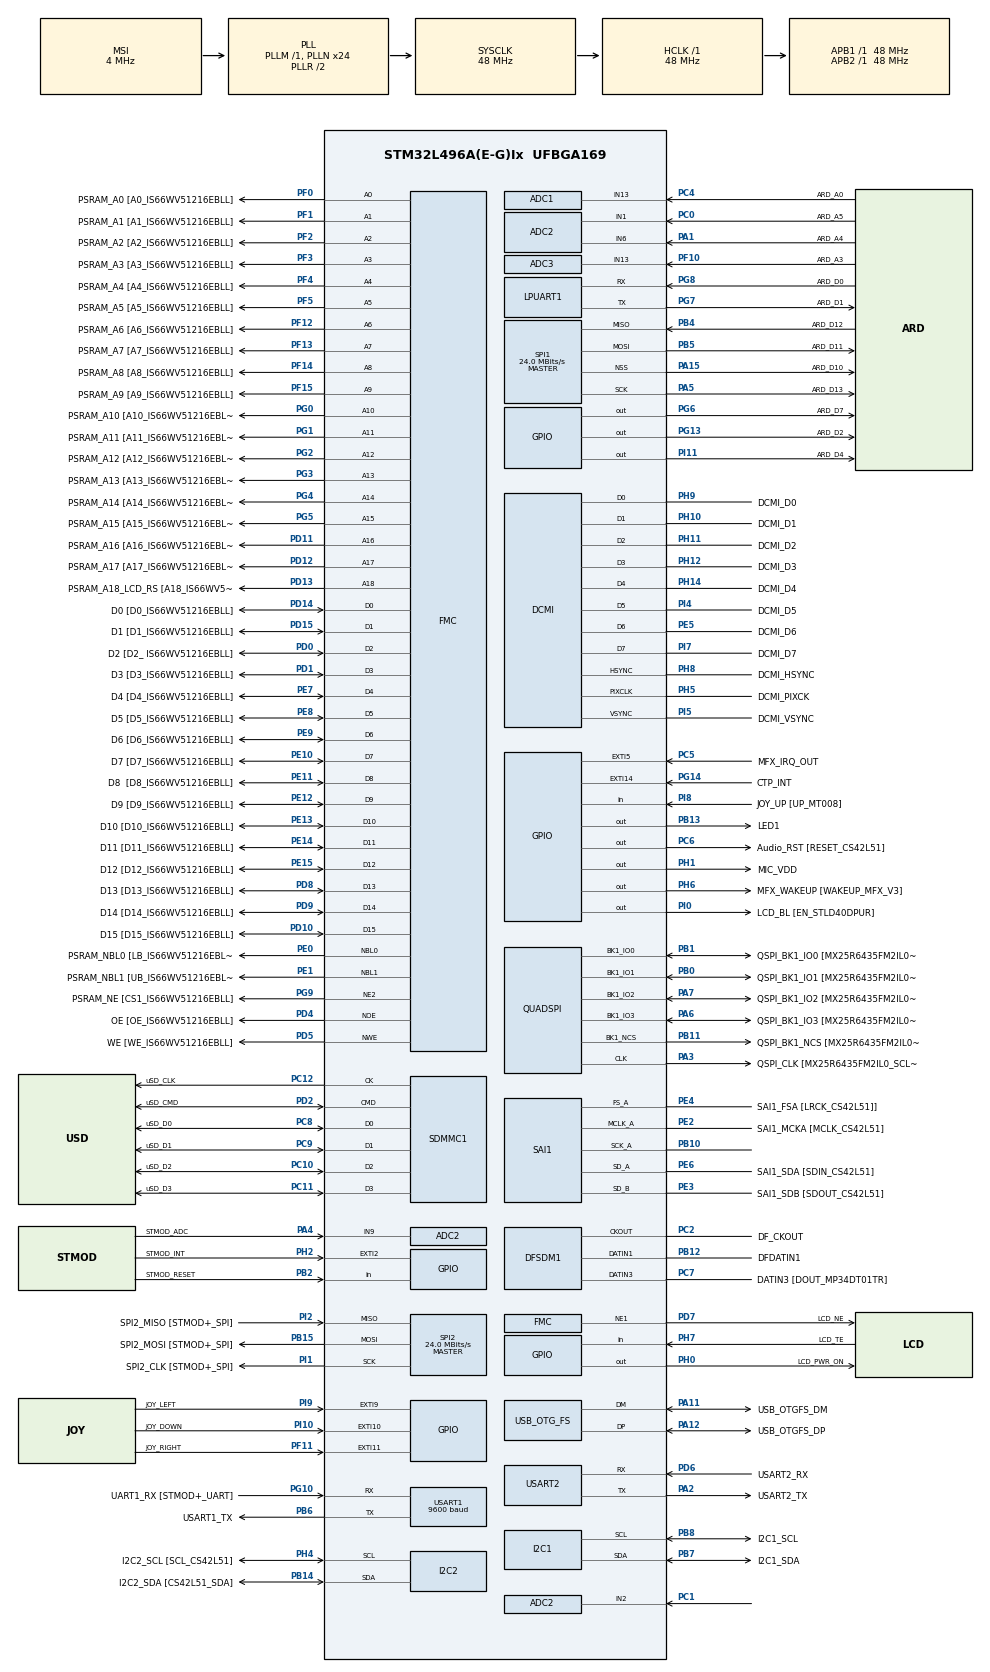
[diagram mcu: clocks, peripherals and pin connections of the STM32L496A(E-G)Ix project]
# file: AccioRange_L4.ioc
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ADC1.Channel-0\#ChannelRegularConversion=ADC_CHANNEL_13
ADC1.NbrOfConversionFlag=1
ADC1.OffsetNumber-0\#ChannelRegularConversion=ADC_OFFSET_NONE
ADC1.Rank-0\#ChannelRegularConversion=1
ADC1.Resolution=ADC_RESOLUTION_10B
ADC1.SamplingTime-0\#ChannelRegularConversion=ADC_SAMPLETIME_2CYCLES_5
ADC1.master=1
ADC2.Channel-0\#ChannelRegularConversion=ADC_CHANNEL_9
ADC2.NbrOfConversionFlag=1
ADC2.OffsetNumber-0\#ChannelRegularConversion=ADC_OFFSET_NONE
ADC2.Rank-0\#ChannelRegularConversion=1
ADC2.SamplingTime-0\#ChannelRegularConversion=ADC_SAMPLETIME_2CYCLES_5
ADC3.Channel-0\#ChannelRegularConversion=ADC_CHANNEL_13
ADC3.NbrOfConversionFlag=1
ADC3.OffsetNumber-0\#ChannelRegularConversion=ADC_OFFSET_NONE
ADC3.Rank-0\#ChannelRegularConversion=1
ADC3.SamplingTime-0\#ChannelRegularConversion=ADC_SAMPLETIME_2CYCLES_5
DCMI.JPEGMode=DCMI_JPEG_DISABLE
I2C1.Timing=0x20303E5D
I2C2.Timing=0x20303E5D
LPUART1.WordLength=UART_WORDLENGTH_8B
Mcu.Family=STM32L4
Mcu.Name=STM32L496A(E-G)Ix
Mcu.Package=UFBGA169
NVIC.EXTI15_10_IRQn=true\:0\:0\:false\:false\:true\:true\:true\:true
NVIC.EXTI9_5_IRQn=true\:0\:0\:false\:false\:true\:true\:true\:true
NVIC.OTG_FS_IRQn=true\:0\:0\:false\:false\:true\:true\:true\:true
NVIC.PriorityGroup=NVIC_PRIORITYGROUP_4
NVIC.TIM6_DAC_IRQn=true\:0\:0\:false\:false\:true\:true\:true\:true
PA0.GPIO_Label=STMOD_PWM
PA0.Mode=SYS_WakeUp0
PA0.Signal=SYS_WKUP1
PA1.GPIO_Label=ARD_A4
PA1.Signal=ADCx_IN6
PA10.GPIO_Label=USB_OTGFS_ID
PA10.Signal=USB_OTG_FS_ID
PA11.GPIO_Label=USB_OTGFS_DM
PA11.Mode=Device_Only
PA11.Signal=USB_OTG_FS_DM
PA12.GPIO_Label=USB_OTGFS_DP
PA12.Mode=Device_Only
PA12.Signal=USB_OTG_FS_DP
PA13\ (JTMS/SWDIO).GPIO_Label=SWDIO
PA13\ (JTMS/SWDIO).Mode=Serial_Wire
PA13\ (JTMS/SWDIO).Signal=SYS_JTMS-SWDIO
PA14\ (JTCK/SWCLK).GPIO_Label=SWCLK
PA14\ (JTCK/SWCLK).Mode=Serial_Wire
PA14\ (JTCK/SWCLK).Signal=SYS_JTCK-SWCLK
PA15\ (JTDI).GPIO_Label=ARD_D10
PA15\ (JTDI).Mode=NSS_Signal_Hard_Output
PA15\ (JTDI).Signal=SPI1_NSS
PA2.GPIO_Label=USART2_TX
PA2.Mode=Asynchronous
PA2.Signal=USART2_TX
PA3.GPIO_Label=QSPI_CLK [MX25R6435FM2IL0_SCLK]
PA3.Mode=Single Bank 1
PA3.Signal=QUADSPI_CLK
PA4.GPIO_Label=STMOD_ADC
PA4.Signal=ADCx_IN9
PA5.GPIO_Label=ARD_D13
PA5.Mode=Full_Duplex_Master
PA5.Signal=SPI1_SCK
PA6.GPIO_Label=QSPI_BK1_IO3 [MX25R6435FM2IL0_SIO3]
PA6.Mode=Single Bank 1
PA6.Signal=QUADSPI_BK1_IO3
PA7.GPIO_Label=QSPI_BK1_IO2 [MX25R6435FM2IL0_SIO2]
PA7.Mode=Single Bank 1
PA7.Signal=QUADSPI_BK1_IO2
PA8.GPIO_Label=DCMI_CLK
PA8.Signal=LPTIM2_OUT
PA9.GPIO_Label=USB_OTGFS_VBUS
PA9.Signal=USB_OTG_FS_VBUS
PB0.GPIO_Label=QSPI_BK1_IO1 [MX25R6435FM2IL0_SIO1]
PB0.Mode=Single Bank 1
PB0.Signal=QUADSPI_BK1_IO1
PB1.GPIO_Label=QSPI_BK1_IO0 [MX25R6435FM2IL0_SIO0]
PB1.Mode=Single Bank 1
PB1.Signal=QUADSPI_BK1_IO0
PB10.Mode=SAI_A_MasterWithClock
PB10.Signal=SAI1_SCK_A
PB11.GPIO_Label=QSPI_BK1_NCS [MX25R6435FM2IL0_CS]
PB11.Mode=Single Bank 1
PB11.Signal=QUADSPI_BK1_NCS
PB12.GPIO_Label=DFDATIN1
PB12.Signal=S_DATAIN1DFSDM1
PB13.GPIO_Label=LED1
PB13.GPIO_ModeDefaultOutputPP=GPIO_MODE_OUTPUT_OD
PB13.GPIO_PuPd=GPIO_NOPULL
PB13.Signal=GPIO_Output
PB14.GPIO_Label=I2C2_SDA [CS42L51_SDA]
PB14.GPIO_Pu=GPIO_PULLUP
PB14.Mode=I2C
PB14.Signal=I2C2_SDA
PB15.GPIO_Label=SPI2_MOSI [STMOD+_SPI]
PB15.Mode=Full_Duplex_Master
PB15.Signal=SPI2_MOSI
PB2.GPIO_Label=STMOD_RESET
PB2.Signal=GPIO_Input
PB3\ (JTDO/TRACESWO).GPIO_Label=SWO
PB3\ (JTDO/TRACESWO).Signal=SYS_JTDO-SWO
PB4\ (NJTRST).GPIO_Label=ARD_D12
PB4\ (NJTRST).Mode=Full_Duplex_Master
PB4\ (NJTRST).Signal=SPI1_MISO
PB5.GPIO_Label=ARD_D11
PB5.Mode=Full_Duplex_Master
PB5.Signal=SPI1_MOSI
PB6.GPIO_Label=USART1_TX
PB6.Mode=Asynchronous
PB6.Signal=USART1_TX
PB7.GPIO_Label=I2C1_SDA
PB7.GPIO_Pu=GPIO_PULLUP
PB7.Mode=I2C
PB7.Signal=I2C1_SDA
PB8.GPIO_Label=I2C1_SCL
PB8.GPIO_Pu=GPIO_PULLUP
PB8.Mode=I2C
PB8.Signal=I2C1_SCL
PB9.GPIO_Label=ARD_D5
PB9.Signal=S_TIM4_CH4
PC0.GPIO_Label=ARD_A5
PC0.Signal=ADCx_IN1
PC1.Signal=ADCx_IN2
PC10.GPIO_Label=uSD_D2
PC10.Mode=SD_4_bits_Wide_bus
PC10.Signal=SDMMC1_D2
PC11.GPIO_Label=uSD_D3
PC11.Mode=SD_4_bits_Wide_bus
PC11.Signal=SDMMC1_D3
PC12.GPIO_Label=uSD_CLK
PC12.Mode=SD_4_bits_Wide_bus
PC12.Signal=SDMMC1_CK
PC13.GPIO_Label=JOY_SEL [Selection_MT008]
PC13.Mode=SYS_WakeUp1
PC13.Signal=SYS_WKUP2
PC14-OSC32_IN\ (PC14).Mode=LSE-External-Oscillator
PC14-OSC32_IN\ (PC14).Signal=RCC_OSC32_IN
PC15-OSC32_OUT\ (PC15).Mode=LSE-External-Oscillator
PC15-OSC32_OUT\ (PC15).Signal=RCC_OSC32_OUT
PC2.GPIO_Label=DF_CKOUT
PC2.Signal=S_CKOUTDFSDM1
PC3.GPIO_Label=ARD_A2
PC3.Signal=ADCx_IN4
PC4.GPIO_Label=ARD_A0
PC4.Signal=ADCx_IN13
PC5.GPIO_Label=MFX_IRQ_OUT
PC5.Signal=GPXTI5
PC6.GPIO_Label=Audio_RST [RESET_CS42L51]
PC6.Signal=GPIO_Output
PC7.GPIO_Label=DATIN3 [DOUT_MP34DT01TR]
PC7.Signal=S_DATAIN3DFSDM1
PC8.GPIO_Label=uSD_D0
PC8.Mode=SD_4_bits_Wide_bus
PC8.Signal=SDMMC1_D0
PC9.GPIO_Label=uSD_D1
PC9.Mode=SD_4_bits_Wide_bus
PC9.Signal=SDMMC1_D1
PD0.GPIO_Label=D2 [D2_ IS66WV51216EBLL]
PD0.Signal=FMC_D2_DA2
PD1.GPIO_Label=D3 [D3_IS66WV51216EBLL]
PD1.Signal=FMC_D3_DA3
PD10.GPIO_Label=D15 [D15_IS66WV51216EBLL]
PD10.Signal=FMC_D15_DA15
PD11.GPIO_Label=PSRAM_A16 [A16_IS66WV51216EBLL]
PD11.Signal=FMC_A16_CLE
PD12.GPIO_Label=PSRAM_A17 [A17_IS66WV51216EBLL]
PD12.Signal=FMC_A17_ALE
PD13.GPIO_Label=PSRAM_A18_LCD_RS [A18_IS66WV51216EBLL]
PD13.Signal=FMC_A18
PD14.GPIO_Label=D0 [D0_IS66WV51216EBLL]
PD14.Signal=FMC_D0_DA0
PD15.GPIO_Label=D1 [D1_IS66WV51216EBLL]
PD15.Signal=FMC_D1_DA1
PD2.GPIO_Label=uSD_CMD
PD2.Mode=SD_4_bits_Wide_bus
PD2.Signal=SDMMC1_CMD
PD4.GPIO_Label=OE [OE_IS66WV51216EBLL]
PD4.Signal=FMC_NOE
PD5.GPIO_Label=WE [WE_IS66WV51216EBLL]
PD5.Signal=FMC_NWE
PD6.GPIO_Label=USART2_RX
PD6.Mode=Asynchronous
PD6.Signal=USART2_RX
PD7.GPIO_Label=LCD_NE
PD7.Mode=NorPsramChipSelect1_2
PD7.Signal=FMC_NE1
PD8.GPIO_Label=D13 [D13_IS66WV51216EBLL]
PD8.Signal=FMC_D13_DA13
PD9.GPIO_Label=D14 [D14_IS66WV51216EBLL]
PD9.Signal=FMC_D14_DA14
PE0.GPIO_Label=PSRAM_NBL0 [LB_IS66WV51216EBLL]
PE0.Signal=FMC_NBL0
PE1.GPIO_Label=PSRAM_NBL1 [UB_IS66WV51216EBLL]
PE1.Signal=FMC_NBL1
PE10.GPIO_Label=D7 [D7_IS66WV51216EBLL]
PE10.Signal=FMC_D7_DA7
PE11.GPIO_Label=D8  [D8_IS66WV51216EBLL]
PE11.Signal=FMC_D8_DA8
PE12.GPIO_Label=D9 [D9_IS66WV51216EBLL]
PE12.Signal=FMC_D9_DA9
PE13.GPIO_Label=D10 [D10_IS66WV51216EBLL]
PE13.Signal=FMC_D10_DA10
PE14.GPIO_Label=D11 [D11_IS66WV51216EBLL]
PE14.Signal=FMC_D11_DA11
PE15.GPIO_Label=D12 [D12_IS66WV51216EBLL]
PE15.Signal=FMC_D12_DA12
PE2.GPIO_Label=SAI1_MCKA [MCLK_CS42L51]
PE2.Mode=SAI_A_MasterWithClock
PE2.Signal=SAI1_MCLK_A
PE3.GPIO_Label=SAI1_SDB [SDOUT_CS42L51]
PE3.Mode=SAI_B_SyncSlave
PE3.Signal=SAI1_SD_B
PE4.GPIO_Label=SAI1_FSA [LRCK_CS42L51]]
PE4.Mode=SAI_A_MasterWithClock
PE4.Signal=SAI1_FS_A
PE5.GPIO_Label=DCMI_D6
PE5.Mode=Slave_8_bits_External_Synchro
PE5.Signal=DCMI_D6
PE6.GPIO_Label=SAI1_SDA [SDIN_CS42L51]
PE6.Mode=SAI_A_MasterWithClock
PE6.Signal=SAI1_SD_A
PE7.GPIO_Label=D4 [D4_IS66WV51216EBLL]
PE7.Signal=FMC_D4_DA4
PE8.GPIO_Label=D5 [D5_IS66WV51216EBLL]
PE8.Signal=FMC_D5_DA5
PE9.GPIO_Label=D6 [D6_IS66WV51216EBLL]
PE9.Signal=FMC_D6_DA6
PF0.GPIO_Label=PSRAM_A0 [A0_IS66WV51216EBLL]
PF0.Signal=FMC_A0
PF1.GPIO_Label=PSRAM_A1 [A1_IS66WV51216EBLL]
PF1.Signal=FMC_A1
PF10.GPIO_Label=ARD_A3
PF10.Mode=IN13-Single-Ended
PF10.Signal=ADC3_IN13
PF11.GPIO_Label=JOY_RIGHT
PF11.GPIO_PuPd=GPIO_PULLDOWN
PF11.Signal=GPXTI11
PF12.GPIO_Label=PSRAM_A6 [A6_IS66WV51216EBLL]
PF12.Signal=FMC_A6
PF13.GPIO_Label=PSRAM_A7 [A7_IS66WV51216EBLL]
PF13.Signal=FMC_A7
PF14.GPIO_Label=PSRAM_A8 [A8_IS66WV51216EBLL]
PF14.Signal=FMC_A8
PF15.GPIO_Label=PSRAM_A9 [A9_IS66WV51216EBLL]
PF15.Signal=FMC_A9
PF2.GPIO_Label=PSRAM_A2 [A2_IS66WV51216EBLL]
PF2.Signal=FMC_A2
PF3.GPIO_Label=PSRAM_A3 [A3_IS66WV51216EBLL]
PF3.Signal=FMC_A3
PF4.GPIO_Label=PSRAM_A4 [A4_IS66WV51216EBLL]
PF4.Signal=FMC_A4
PF5.GPIO_Label=PSRAM_A5 [A5_IS66WV51216EBLL]
PF5.Signal=FMC_A5
PG0.GPIO_Label=PSRAM_A10 [A10_IS66WV51216EBLL]
PG0.Signal=FMC_A10
PG1.GPIO_Label=PSRAM_A11 [A11_IS66WV51216EBLL]
PG1.Signal=FMC_A11
PG10.GPIO_Label=UART1_RX [STMOD+_UART]
PG10.Mode=Asynchronous
PG10.Signal=USART1_RX
PG11.GPIO_Label=UART1_CTS [STMOD+_UART]
PG11.Signal=USART1_CTS
PG12.GPIO_Label=UART1_RTS [STMOD+_UART]
PG12.Signal=USART1_RTS
PG13.GPIO_Label=ARD_D2
PG13.Signal=GPIO_Output
PG14.GPIO_Label=CTP_INT
PG14.Signal=GPXTI14
PG2.GPIO_Label=PSRAM_A12 [A12_IS66WV51216EBLL]
PG2.Signal=FMC_A12
PG3.GPIO_Label=PSRAM_A13 [A13_IS66WV51216EBLL]
PG3.Signal=FMC_A13
PG4.GPIO_Label=PSRAM_A14 [A14_IS66WV51216EBLL]
PG4.Signal=FMC_A14
PG5.GPIO_Label=PSRAM_A15 [A15_IS66WV51216EBLL]
PG5.Signal=FMC_A15
PG6.GPIO_Label=ARD_D7
PG6.Signal=GPIO_Output
PG7.GPIO_Label=ARD_D1
PG7.Mode=Asynchronous
PG7.Signal=LPUART1_TX
PG8.GPIO_Label=ARD_D0
PG8.Mode=Asynchronous
PG8.Signal=LPUART1_RX
PG9.GPIO_Label=PSRAM_NE [CS1_IS66WV51216EBLL]
PG9.Mode=NorPsramChipSelect2_1
PG9.Signal=FMC_NE2
PH0-OSC_IN\ (PH0).GPIO_Label=LCD_PWR_ON
PH0-OSC_IN\ (PH0).Signal=GPIO_Output
PH1-OSC_OUT\ (PH1).GPIO_Label=MIC_VDD
PH1-OSC_OUT\ (PH1).Signal=GPIO_Output
PH10.GPIO_Label=DCMI_D1
PH10.Mode=Slave_8_bits_External_Synchro
PH10.Signal=DCMI_D1
PH11.GPIO_Label=DCMI_D2
PH11.Mode=Slave_8_bits_External_Synchro
PH11.Signal=DCMI_D2
PH12.GPIO_Label=DCMI_D3
PH12.Mode=Slave_8_bits_External_Synchro
PH12.Signal=DCMI_D3
PH13.GPIO_Label=ARD_D9
PH13.Signal=TIM8_CH1N
PH14.GPIO_Label=DCMI_D4
PH14.Mode=Slave_8_bits_External_Synchro
PH14.Signal=DCMI_D4
PH15.GPIO_Label=ARD_D3
PH15.Signal=TIM8_CH3N
PH2.GPIO_Label=STMOD_INT
PH2.Signal=GPXTI2
PH4.GPIO_Label=I2C2_SCL [SCL_CS42L51]
PH4.GPIO_Pu=GPIO_PULLUP
PH4.Mode=I2C
PH4.Signal=I2C2_SCL
PH5.GPIO_Label=DCMI_PIXCK
PH5.Mode=Slave_8_bits_External_Synchro
PH5.Signal=DCMI_PIXCLK
PH6.GPIO_Label=MFX_WAKEUP [WAKEUP_MFX_V3]
PH6.Signal=GPIO_Output
PH7.GPIO_Label=LCD_TE
PH7.Signal=GPIO_Input
PH8.GPIO_Label=DCMI_HSYNC
PH8.Mode=Slave_8_bits_External_Synchro
PH8.Signal=DCMI_HSYNC
PH9.GPIO_Label=DCMI_D0
PH9.Mode=Slave_8_bits_External_Synchro
PH9.Signal=DCMI_D0
PI0.GPIO_Label=LCD_BL [EN_STLD40DPUR]
PI0.Signal=GPIO_Output
PI1.GPIO_Label=SPI2_CLK [STMOD+_SPI]
PI1.Mode=Full_Duplex_Master
PI1.Signal=SPI2_SCK
PI10.GPIO_Label=JOY_DOWN
PI10.GPIO_PuPd=GPIO_PULLDOWN
PI10.Signal=GPXTI10
PI11.GPIO_Label=ARD_D4
PI11.Signal=GPIO_Output
PI2.GPIO_Label=SPI2_MISO [STMOD+_SPI]
PI2.Mode=Full_Duplex_Master
PI2.Signal=SPI2_MISO
PI4.GPIO_Label=DCMI_D5
PI4.Mode=Slave_8_bits_External_Synchro
PI4.Signal=DCMI_D5
PI5.GPIO_Label=DCMI_VSYNC
PI5.Mode=Slave_8_bits_External_Synchro
PI5.Signal=DCMI_VSYNC
PI6.GPIO_Label=ARD_D6
PI6.Signal=S_TIM8_CH2
PI7.GPIO_Label=DCMI_D7
PI7.Mode=Slave_8_bits_External_Synchro
PI7.Signal=DCMI_D7
PI8.GPIO_Label=JOY_UP [UP_MT008]
PI8.GPIO_PuPd=GPIO_PULLDOWN
PI8.Signal=GPIO_Input
PI9.GPIO_Label=JOY_LEFT
PI9.GPIO_ModeDefaultEXTI=GPIO_MODE_EVT_RISING
PI9.GPIO_PuPd=GPIO_PULLDOWN
PI9.Signal=GPXTI9
ProjectManager.HeapSize=0x200
ProjectManager.StackSize=0x400
ProjectManager.TargetToolchain=STM32CubeIDE
QUADSPI.ClockPrescaler=2
QUADSPI.FifoThreshold=4
QUADSPI.FlashSize=23
QUADSPI.SampleShifting=QSPI_SAMPLE_SHIFTING_HALFCYCLE
RCC.ADCFreq_Value=48000000
RCC.AHBFreq_Value=48000000
RCC.APB1Freq_Value=48000000
RCC.APB1TimFreq_Value=48000000
RCC.APB2Freq_Value=48000000
RCC.APB2TimFreq_Value=48000000
RCC.CortexFreq_Value=48000000
RCC.HCLKFreq_Value=48000000
RCC.HSE_VALUE=8000000
RCC.HSI48_VALUE=48000000
RCC.HSI_VALUE=16000000
RCC.MSI_VALUE=4000000
RCC.PLLN=24
RCC.PLLSAI1N=24
RCC.SYSCLKFreq_VALUE=48000000
RCC.SYSCLKSource=RCC_SYSCLKSOURCE_PLLCLK
RCC.USBFreq_Value=48000000
RCC.VCOOutputFreq_Value=96000000
SAI1.ErrorAudioFreq-SAI_A_MasterWithClock=-2.34 %
SAI1.Instance-SAI_A_MasterWithClock=SAI$Index_Block_A
SAI1.Instance-SAI_B_SyncSlave=SAI$Index_Block_B
SAI1.MClockEnable-SAI_A_MasterWithClock=SAI_MASTERCLOCK_ENABLE
SAI1.RealAudioFreq-SAI_A_MasterWithClock=187.5 KHz
SAI1.VirtualMode-SAI_A_MasterWithClock=VM_MASTER
SAI1.VirtualMode-SAI_B_SyncSlave=VM_SLAVE
SH.ADCx_IN1.0=ADC2_IN1,IN1-Single-Ended
SH.ADCx_IN13.0=ADC1_IN13,IN13-Single-Ended
SH.ADCx_IN2.0=ADC2_IN2,IN2-Single-Ended
SH.ADCx_IN4.0=ADC1_IN4
SH.ADCx_IN6.0=ADC2_IN6,IN6-Single-Ended
SH.ADCx_IN9.0=ADC2_IN9,IN9-Single-Ended
SH.FMC_A0.0=FMC_A0,18b-a1
SH.FMC_A1.0=FMC_A1,18b-a1
SH.FMC_A10.0=FMC_A10,18b-a1
SH.FMC_A11.0=FMC_A11,18b-a1
SH.FMC_A12.0=FMC_A12,18b-a1
SH.FMC_A13.0=FMC_A13,18b-a1
SH.FMC_A14.0=FMC_A14,18b-a1
SH.FMC_A15.0=FMC_A15,18b-a1
SH.FMC_A16_CLE.0=FMC_A16,18b-a1
SH.FMC_A17_ALE.0=FMC_A17,18b-a1
SH.FMC_A18.0=FMC_A18,A18_2
SH.FMC_A2.0=FMC_A2,18b-a1
SH.FMC_A3.0=FMC_A3,18b-a1
SH.FMC_A4.0=FMC_A4,18b-a1
SH.FMC_A5.0=FMC_A5,18b-a1
SH.FMC_A6.0=FMC_A6,18b-a1
SH.FMC_A7.0=FMC_A7,18b-a1
SH.FMC_A8.0=FMC_A8,18b-a1
SH.FMC_A9.0=FMC_A9,18b-a1
SH.FMC_D0_DA0.0=FMC_D0,16b-d1
SH.FMC_D0_DA0.1=FMC_D0,16b-d2
SH.FMC_D10_DA10.0=FMC_D10,16b-d1
SH.FMC_D10_DA10.1=FMC_D10,16b-d2
SH.FMC_D11_DA11.0=FMC_D11,16b-d1
SH.FMC_D11_DA11.1=FMC_D11,16b-d2
SH.FMC_D12_DA12.0=FMC_D12,16b-d1
SH.FMC_D12_DA12.1=FMC_D12,16b-d2
SH.FMC_D13_DA13.0=FMC_D13,16b-d1
SH.FMC_D13_DA13.1=FMC_D13,16b-d2
SH.FMC_D14_DA14.0=FMC_D14,16b-d1
SH.FMC_D14_DA14.1=FMC_D14,16b-d2
SH.FMC_D15_DA15.0=FMC_D15,16b-d1
SH.FMC_D15_DA15.1=FMC_D15,16b-d2
SH.FMC_D1_DA1.0=FMC_D1,16b-d1
SH.FMC_D1_DA1.1=FMC_D1,16b-d2
SH.FMC_D2_DA2.0=FMC_D2,16b-d1
SH.FMC_D2_DA2.1=FMC_D2,16b-d2
SH.FMC_D3_DA3.0=FMC_D3,16b-d1
SH.FMC_D3_DA3.1=FMC_D3,16b-d2
SH.FMC_D4_DA4.0=FMC_D4,16b-d1
SH.FMC_D4_DA4.1=FMC_D4,16b-d2
SH.FMC_D5_DA5.0=FMC_D5,16b-d1
SH.FMC_D5_DA5.1=FMC_D5,16b-d2
SH.FMC_D6_DA6.0=FMC_D6,16b-d1
SH.FMC_D6_DA6.1=FMC_D6,16b-d2
SH.FMC_D7_DA7.0=FMC_D7,16b-d1
SH.FMC_D7_DA7.1=FMC_D7,16b-d2
SH.FMC_D8_DA8.0=FMC_D8,16b-d1
SH.FMC_D8_DA8.1=FMC_D8,16b-d2
SH.FMC_D9_DA9.0=FMC_D9,16b-d1
SH.FMC_D9_DA9.1=FMC_D9,16b-d2
SH.FMC_NBL0.0=FMC_NBL0,2ByteEnable1
SH.FMC_NBL1.0=FMC_NBL1,2ByteEnable1
SH.FMC_NOE.0=FMC_NOE,Sram1
SH.FMC_NOE.1=FMC_NOE,Lcd2
SH.FMC_NWE.0=FMC_NWE,Sram1
SH.FMC_NWE.1=FMC_NWE,Lcd2
SH.S_CKOUTDFSDM1.0=DFSDM1_CKOUT,PDM_SPI_Input_from_ch23_and_Internal_Clock
SH.S_CKOUTDFSDM1.1=DFSDM1_CKOUT,PDM_SPI_input_from_ch1_and_internal_clock
SH.S_DATAIN1DFSDM1.0=DFSDM1_DATIN1,PDM_SPI_input_from_ch1_and_internal_clock
SH.S_DATAIN3DFSDM1.0=DFSDM1_DATIN3,PDM_SPI_Input_from_ch23_and_Internal_Clock
SH.S_TIM4_CH4.0=TIM4_CH4
SH.S_TIM8_CH2.0=TIM8_CH2
SPI1.CalculateBaudRate=24.0 MBits/s
SPI1.Direction=SPI_DIRECTION_2LINES
SPI1.Mode=SPI_MODE_MASTER
SPI1.VirtualNSS=VM_NSSHARD
SPI1.VirtualType=VM_MASTER
SPI2.CalculateBaudRate=24.0 MBits/s
SPI2.Direction=SPI_DIRECTION_2LINES
SPI2.Mode=SPI_MODE_MASTER
SPI2.VirtualType=VM_MASTER
TIM6.Period=19200-1
TIM6.Prescaler=100-1
USART1.BaudRate=9600
USART1.VirtualMode-Asynchronous=VM_ASYNC
USART2.VirtualMode-Asynchronous=VM_ASYNC
USB_DEVICE.CLASS_NAME_FS=CDC
USB_DEVICE.VirtualMode=Cdc
USB_DEVICE.VirtualModeFS=Cdc_FS
USB_OTG_FS.VirtualMode=Device_Only
VP_TIM6_VS_ClockSourceINT.Mode=Enable_Timer
VP_USB_DEVICE_VS_USB_DEVICE_CDC_FS.Mode=CDC_FS
board=STM32L496G-DISCO

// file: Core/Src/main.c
/* USER CODE BEGIN Header */
/**
  ******************************************************************************
  * @file           : main.c
  * @brief          : Main program body
  ******************************************************************************
  * @attention
  *
  * Copyright (c) 2022 STMicroelectronics.
  * All rights reserved.
  *
  * This software is licensed under terms that can be found in the LICENSE file
  * in the root directory of this software component.
  * If no LICENSE file comes with this software, it is provided AS-IS.
  *
  ******************************************************************************
  */
/* USER CODE END Header */
#include "main.h"
#include "adc.h"
#include "dcmi.h"
#include "dfsdm.h"
#include "i2c.h"
#include "usart.h"
#include "quadspi.h"
#include "sai.h"
#include "sdmmc.h"
#include "spi.h"
#include "tim.h"
#include "usb_device.h"
#include "gpio.h"
#include "fmc.h"

/* USER CODE BEGIN Includes */
// be sure to add these directories to the build paths in project properties
#include <stdbool.h>
#include "vl53l0x_api.h"
#include "stm32l496g_discovery.h"
#include "stm32l496g_discovery_lcd.h"
#include "stm32l496g_discovery_ts.h"
/* USER CODE END Includes */

/* USER CODE BEGIN PD */
#define TIMED_RANGING_PERIOD    40    // sensor sampling period in ms
#define LED_TOGGLE_DELAY        100   // heartbeat led
#define PWR_ANALYSIS 						1     // set to 1 to have longer delays when powering down peripherals
#define PWR_ANALYSIS_DELAY			1000  // duration of delay
#define RANGER_SAMPLE_RATE      20    // samples per second
#define PROFILING_TIM           0     // set to 1 to trigger test point whenever timer interrupt fires
#define PROFILING_SAMPLES       1     // set to 1 to trigger test point during processing of samples
/* USER CODE END PD */

/* USER CODE BEGIN PV */

// touch screen related
TS_StateTypeDef ts_result;
uint32_t last_ts;
char buf[20];

// states related
bool SAMPLE_SENSOR = false;
bool DIMMED_SCREEN = false;
bool SLEEP_MODE_ACTIVE = false;
bool ENTER_SLEEP_MODE = false;
bool BT_ENABLED = true;
bool SEND_ENABLED = true;

// led related
bool led_on = false;
static uint32_t TimingDelay;

// ui related // UI234
struct Bubble {
   uint16_t x;
   uint16_t y;
   uint16_t radius;
   uint16_t hit_diameter;
   bool selected;
   uint16_t colour_active;
   uint16_t colour_inactive;
   bool redraw;
   uint8_t type;
   uint32_t last_selected;
};
uint8_t num_bubbles = 4;
struct Bubble ui_bubbles[4];
bool bubble_label_redraw = true;

// tof related
VL53L0X_RangingMeasurementData_t RangingMeasurementData; // global ranging struct

VL53L0X_Dev_t VL53L0XDev = {
		.Id=0,
		.DevLetter='e',
		.I2cHandle=&hi2c1,
		.I2cDevAddr=0x29 // EK: documentation says address is 0x29, why did the code say 0x52?
};

uint8_t VhvSettings;
uint8_t PhaseCal;
uint32_t refSpadCount;
uint8_t isApertureSpads;

// sampling related
struct Ranger {
	uint16_t max;
	uint16_t min;

	uint16_t raw;
	float raw_mm;

	float raw_sum;
	uint16_t sum_count;
	uint16_t sum_skip;

	float mm_avg;

	uint16_t record_index;
	float records[300];
	bool process_records;
	float record_sum;

	float val;
};
uint8_t num_rangers = 2;
struct Ranger rangers[2];

uint16_t NUM_RECORDS = 5;
uint16_t MAX_RECORDS = 300; // =5mins*60seconds

float sonar_mm_avg = 0.0;
float tof_mm_avg = 0.0;

float result_distance = 0.0;
bool UPDATE_RESULT = false;
float alpha = 0.75; // weight of tof

/* USER CODE END PV */

void SystemClock_Config(void);
void PeriphCommonClock_Config(void);
/* USER CODE BEGIN PFP */

// sleep mode related
void reconfigureFromSleep(void);
void awakeFromSleep(void);
void enterSleep(void);

// ui related
void uiSetup(void);
void drawBubble(struct Bubble *bubble);
void deselectBubbles(uint8_t skip);

// tof related
void tofTestRegisterRead(void);

/* USER CODE END PFP */

/* USER CODE BEGIN 0 */

/**
 * Handle Error
 *
 * Set err on display and loop forever
 * @param err Error case code
 */
void HandleError(int err){
    char msg[16];
    sprintf(msg,"Er%d", err);
    while(1){};
}

void HAL_TIM_PeriodElapsedCallback(TIM_HandleTypeDef *htim) {

	if(htim == &htim6) {
		if(PROFILING_TIM) HAL_GPIO_TogglePin(ARD_D7_GPIO_Port, ARD_D7_Pin); // test point for profiling
		SAMPLE_SENSOR = true;
	}

}

/* USER CODE END 0 */

int main(void)
{

  /* MCU Configuration--------------------------------------------------------*/

  /* Reset of all peripherals, Initializes the Flash interface and the Systick. */
  HAL_Init();

  /* Configure the system clock */
  SystemClock_Config();

/* Configure the peripherals common clocks */
  PeriphCommonClock_Config();

  /* Initialize all configured peripherals */
  MX_GPIO_Init();
  MX_ADC1_Init();
  MX_ADC2_Init();
  MX_ADC3_Init();
  MX_DCMI_Init();
  MX_DFSDM1_Init();
  MX_FMC_Init();
  MX_I2C1_Init();
  MX_I2C2_Init();
  MX_LPUART1_UART_Init();
  MX_USART1_UART_Init();
  MX_USART2_UART_Init();
  MX_QUADSPI_Init();
  MX_SAI1_Init();
  MX_SDMMC1_SD_Init();
  MX_SPI1_Init();
  MX_SPI2_Init();
  MX_USB_DEVICE_Init();
  MX_TIM6_Init();
  /* USER CODE BEGIN 2 */
  // above: MX_SDMMC1_SD_Init(); has to be commented out to not be called

  // lcd init
	if (BSP_LCD_InitEx(LCD_ORIENTATION_LANDSCAPE) == LCD_ERROR) {
		Error_Handler();
	}

	// touchscreen init
	if(BSP_TS_InitEx(BSP_LCD_GetXSize(), BSP_LCD_GetYSize(), LCD_ORIENTATION_LANDSCAPE) != TS_OK) {
		Error_Handler();
	}

	// LED GPIO
	BSP_LED_Init(LED2_PIN); // LD1
	BSP_LED_On(LED2_PIN); // LD1 orange turns on
	HAL_GPIO_WritePin(LED2_GPIO_PORT, LED2_PIN, GPIO_PIN_RESET); // LD2 green turns on
	// LD3 is attached to ARD_D13, which is not an output, it's attached to SPI
	HAL_GPIO_WritePin(ARD_D4_GPIO_Port, ARD_D4_Pin, GPIO_PIN_RESET); // laser
	HAL_GPIO_WritePin(ARD_D7_GPIO_Port, ARD_D7_Pin, GPIO_PIN_RESET); // test point: timer frequency
	HAL_GPIO_WritePin(ARD_D2_GPIO_Port, ARD_D2_Pin, GPIO_PIN_SET); // turn on BT pwr transistor

	// tof related
	VL53L0X_Dev_t *pDev;
	pDev = &VL53L0XDev;
	tofTestRegisterRead();

	pDev->I2cDevAddr = 0x52;
	pDev->Present = 0;

	int status = VL53L0X_DataInit(pDev);
	if(status == 0) {
			pDev->Present = 1;
	} else {
			printf("VL53L0X_DataInit fail\n");
			return;
	}
	printf("VL53L0X %d Present and initiated to final 0x%x\n", pDev->Id, pDev->I2cDevAddr);
	pDev->Present = 1;

	// Initialize the device in continuous ranging mode
	VL53L0X_StaticInit(pDev);
	VL53L0X_PerformRefCalibration(pDev, &VhvSettings, &PhaseCal);
	VL53L0X_PerformRefSpadManagement(pDev, &refSpadCount, &isApertureSpads);
	VL53L0X_SetInterMeasurementPeriodMilliSeconds(pDev, TIMED_RANGING_PERIOD);
	VL53L0X_SetDeviceMode(pDev, VL53L0X_DEVICEMODE_CONTINUOUS_TIMED_RANGING);
	VL53L0X_StartMeasurement(pDev);

	// sampling related
	for(uint8_t i=0; i<num_rangers; i++) {
		struct Ranger *r = &rangers[i];
		r->max = 0;
		r->min = 0;
		r->raw = 0;
		r->raw_mm = 0.0;
		r->raw_sum = 0.0;
		r->sum_count = 0;
		r->sum_skip = 0;
		r->mm_avg = 0.0;
		r->record_index = 0;
		for(uint16_t j=0; j<MAX_RECORDS; j++) {
			r->records[j] = 0.0;
		}
		r->process_records = false;
		r->record_sum = 0.0;
		r->val = 0.0;
	}
	rangers[0].max = 3000; // mm sonar
	rangers[0].min = 150;
	rangers[1].max = 500; // mm tof
	rangers[1].min = 10;

	// ui related
	uiSetup();

	// start timer
  HAL_TIM_Base_Start_IT(&htim6);

  /* USER CODE END 2 */

  /* Infinite loop */
  /* USER CODE BEGIN WHILE */
  while (1)
  {

  	// wake from event, the first state seen after exiting sleep mode
  	if(SLEEP_MODE_ACTIVE) {
			reconfigureFromSleep();
			awakeFromSleep();
			// refresh ui
			for(uint8_t i=0; i<num_bubbles; i++) {
				struct Bubble *b = &ui_bubbles[i];
				b->redraw = true;
			}
			bubble_label_redraw = true;
		}

  	// flag set from button interrupt to enter in to sleep mode
  	if(ENTER_SLEEP_MODE) {
  		enterSleep();
  		HAL_SuspendTick();
			HAL_PWR_EnterSLEEPMode(PWR_MAINREGULATOR_ON, PWR_SLEEPENTRY_WFE); // left button configured as event
  	}

  	// processing the sensor data
  	// sampling every 50 ms
  	// flag set from timer
  	if(SAMPLE_SENSOR) {

  		if(PROFILING_SAMPLES) HAL_GPIO_WritePin(ARD_D7_GPIO_Port, ARD_D7_Pin, GPIO_PIN_SET); // test point for profiling

  		// get sonar adc value
			// "10-bit ADC, divide the ADC output by 2 for the range in inches."
			HAL_ADC_Start(&hadc1);
			HAL_ADC_PollForConversion(&hadc1, HAL_MAX_DELAY);
			rangers[0].raw = HAL_ADC_GetValue(&hadc1);
			rangers[0].raw_mm = (float)(rangers[0].raw/2.0)*2.54*10;

			// get time of flight i2c value
			VL53L0X_GetRangingMeasurementData(pDev, &RangingMeasurementData);
			rangers[1].raw_mm = RangingMeasurementData.RangeMilliMeter; // mm

			// go through each of the rangers
			for(uint8_t i=0; i<num_rangers; i++) {
				struct Ranger *r = &rangers[i];

				// clamp the values between a min and max
				// if it doesn't fit, skip it
				if(r->raw_mm < r->max && r->raw_mm > r->min) {
					r->raw_sum += r->raw_mm;
					r->sum_count++;
					HAL_GPIO_WritePin(ARD_D4_GPIO_Port, ARD_D4_Pin, GPIO_PIN_SET); // laser on
				} else {
					r->sum_skip++;
					HAL_GPIO_WritePin(ARD_D4_GPIO_Port, ARD_D4_Pin, GPIO_PIN_RESET); // laser off
				}

				uint16_t total_sum = r->sum_count + r->sum_skip;

				// check for when the count matches the sample rate
				if(total_sum >= RANGER_SAMPLE_RATE) {

					if(r->sum_count > 0) {
						r->mm_avg = r->raw_sum / (float)r->sum_count; // get the average
					} else {
						r->mm_avg = 0.0; // clamp to 0 if there was nothing added
					}

					// reset the counters
					r->raw_sum = 0;
					r->sum_count = 0;
					r->sum_skip = 0;

					// see if there's enough records ready to make the readout
					if(r->record_index < NUM_RECORDS && r->record_index < MAX_RECORDS) {
						r->records[r->record_index] = r->mm_avg;
						r->record_index++;
					} else {
						r->process_records = true;
					}

				}

				// update our live variables
				if(i==0) {
					sonar_mm_avg = r->mm_avg;
				} else if(i==1) {
					tof_mm_avg = r->mm_avg;
				}

				if(PROFILING_SAMPLES) HAL_GPIO_WritePin(ARD_D7_GPIO_Port, ARD_D7_Pin, GPIO_PIN_RESET); // test point for profiling

			} // end of rangers loop

			// hope all of this takes < 50 ms

  		SAMPLE_SENSOR = false; // set to true by timer
  	}

  	// next, process the records from the data
  	bool ready_to_process = false;
  	uint8_t ready_count = 0;
  	for(uint8_t i=0; i<num_rangers; i++) {
  		struct Ranger *r = &rangers[i];
  		if(r->process_records == true) {
  			ready_count++;
  		}
  	}
  	if(ready_count == num_rangers) {
  		ready_to_process = true;
  	}
  	if(ready_to_process) {

  		for(uint8_t i=0; i<num_rangers; i++) {
				struct Ranger *r = &rangers[i];

				for(uint16_t j=0; j<r->record_index; j++) {
					r->record_sum += r->records[j];
				}

				// record average
				r->val = r->record_sum/r->record_index;

				// reset counters
				r->record_index = 0;
				r->record_sum = 0.0;

				// reset this flag
				r->process_records = false;
			}

  		// hooray! we have the value!
  		result_distance = (alpha*rangers[1].val) + ( (1-alpha)*rangers[0].val);
  		UPDATE_RESULT = true;

  	}

  	// send the resulting distance over bt to our app
  	// UPDATE_RESULT refers to the data processing
  	// SEND_ENABLED refers to the big button on the screen
  	if(UPDATE_RESULT == true && SEND_ENABLED == true) {

  		HAL_GPIO_WritePin(LED2_GPIO_PORT, LED2_PIN, GPIO_PIN_RESET); // LD2 green turns on

			// this should already be on, but let's do it again just in case...
			// turn on BT pwr transistor
  		HAL_GPIO_WritePin(ARD_D2_GPIO_Port, ARD_D2_Pin, GPIO_PIN_SET);

  		// send to uart
  		if(result_distance > 0) {
				sprintf((char*)buf, "%d;", (uint16_t)result_distance);
			} else {
				sprintf((char*)buf, "%d;", -1);
			}
			HAL_UART_Transmit(&huart1, buf, strlen((char*)buf), HAL_MAX_DELAY);

			HAL_GPIO_WritePin(LED2_GPIO_PORT, LED2_PIN, GPIO_PIN_SET); // LD2 green turns off

  		UPDATE_RESULT = false;
  	}

		// update ui
		for(uint8_t i=0; i<num_bubbles; i++) {
			drawBubble(&ui_bubbles[i]);
		}
		if(bubble_label_redraw) {
			BSP_LCD_SetTextColor( LCD_COLOR_DARKGREEN );
			BSP_LCD_SetFont(&Font24);
			//BSP_LCD_DisplayStringAt(0, 90, (uint8_t *)" 10   30   90", LEFT_MODE);
			BSP_LCD_DisplayStringAt(0, 90, (uint8_t *)" 2   5   10", LEFT_MODE);
			bubble_label_redraw = false;
		}

		// update ts
		BSP_TS_GetState(&ts_result);
		uint8_t num_touches = ts_result.touchDetected;

		// wake up the screen on touch
		if(num_touches > 0 && DIMMED_SCREEN == true) {
			BSP_LCD_ScreenDimmingOff();
			DIMMED_SCREEN = false;
			last_ts = HAL_GetTick();
		}

		// hit testing selected bubbles
		for(uint8_t i=0; i<num_touches; i++) {
			Point touch;
			touch.X = ts_result.touchX[i];
			touch.Y = ts_result.touchY[i];

			for(uint8_t j=0; j<num_bubbles; j++) {
				struct Bubble *b = &ui_bubbles[j];

				// hit testing
				if(touch.X < b->x + b->hit_diameter && touch.X > b->x - b->hit_diameter) {
					if(touch.Y < b->y + b->hit_diameter && touch.Y > b->y - b->hit_diameter) {

						if(b->type == 1) { // ui bubbles

							if(!b->selected) { // not selected prior
								b->selected = !b->selected;
								deselectBubbles(j); // "single touch"
								b->redraw = true;
								b->last_selected = HAL_GetTick();

								// update the number of records
								if(j==0) {
									NUM_RECORDS = 2;
								} else if(j==1) {
									NUM_RECORDS = 5;
								} else if(j==2) {
									NUM_RECORDS = 10;
								}

							}

						} else if(b->type == 2) { // go bubble

							if(HAL_GetTick()-b->last_selected > 80) { // 80 ms debounce
								b->selected = !b->selected;
								b->redraw = true;
								b->last_selected = HAL_GetTick();

								SEND_ENABLED = b->selected;
							}

						}

					}
				} // hit testing end

			} // bubble loop end

		} // touches end

		// check for last touch
		// imagine the case where gettick has overflowed, but last_ts has not
		// eg 100-30000
		// abs could be used to prevent this from being a negative number, however
		// in this case, it is not needed, because two unsigned integers being
		// subtracted results in an unsigned integer
		if( HAL_GetTick()-last_ts >= 5000 && DIMMED_SCREEN == false) {
			//BSP_LCD_ScreenDimmingConfig(100, 5, 5, 20); // 100-5=95/5=19*20=380ms
			BSP_LCD_ScreenDimmingConfig(100, 5, 5, 1); // 100-5=95/5=19*20=380ms
			BSP_LCD_ScreenDimmingOn();
			DIMMED_SCREEN = true;
		}

		// led heartbeat
		if(TimingDelay == 0) {
			if(led_on) {
				BSP_LED_On(LED2_PIN); // LD1 orange
			} else {
				BSP_LED_Off(LED2_PIN); // LD1 orange
			}
			led_on = !led_on;
		}

    /* USER CODE END WHILE */

  }
}

void SystemClock_Config(void)
{
  RCC_OscInitTypeDef RCC_OscInitStruct = {0};
  RCC_ClkInitTypeDef RCC_ClkInitStruct = {0};

  /** Configure the main internal regulator output voltage
  */
  if (HAL_PWREx_ControlVoltageScaling(PWR_REGULATOR_VOLTAGE_SCALE1) != HAL_OK)
  {
    Error_Handler();
  }

  /** Configure LSE Drive Capability
  */
  HAL_PWR_EnableBkUpAccess();
  __HAL_RCC_LSEDRIVE_CONFIG(RCC_LSEDRIVE_LOW);

  /** Initializes the RCC Oscillators according to the specified parameters
  * in the RCC_OscInitTypeDef structure.
  */
  RCC_OscInitStruct.OscillatorType = RCC_OSCILLATORTYPE_LSE|RCC_OSCILLATORTYPE_MSI;
  RCC_OscInitStruct.LSEState = RCC_LSE_ON;
  RCC_OscInitStruct.MSIState = RCC_MSI_ON;
  RCC_OscInitStruct.MSICalibrationValue = 0;
  RCC_OscInitStruct.MSIClockRange = RCC_MSIRANGE_6;
  RCC_OscInitStruct.PLL.PLLState = RCC_PLL_ON;
  RCC_OscInitStruct.PLL.PLLSource = RCC_PLLSOURCE_MSI;
  RCC_OscInitStruct.PLL.PLLM = 1;
  RCC_OscInitStruct.PLL.PLLN = 24;
  RCC_OscInitStruct.PLL.PLLP = RCC_PLLP_DIV2;
  RCC_OscInitStruct.PLL.PLLQ = RCC_PLLQ_DIV2;
  RCC_OscInitStruct.PLL.PLLR = RCC_PLLR_DIV2;
  if (HAL_RCC_OscConfig(&RCC_OscInitStruct) != HAL_OK)
  {
    Error_Handler();
  }

  /** Initializes the CPU, AHB and APB buses clocks
  */
  RCC_ClkInitStruct.ClockType = RCC_CLOCKTYPE_HCLK|RCC_CLOCKTYPE_SYSCLK
                              |RCC_CLOCKTYPE_PCLK1|RCC_CLOCKTYPE_PCLK2;
  RCC_ClkInitStruct.SYSCLKSource = RCC_SYSCLKSOURCE_PLLCLK;
  RCC_ClkInitStruct.AHBCLKDivider = RCC_SYSCLK_DIV1;
  RCC_ClkInitStruct.APB1CLKDivider = RCC_HCLK_DIV1;
  RCC_ClkInitStruct.APB2CLKDivider = RCC_HCLK_DIV1;

  if (HAL_RCC_ClockConfig(&RCC_ClkInitStruct, FLASH_LATENCY_2) != HAL_OK)
  {
    Error_Handler();
  }

  /** Enable MSI Auto calibration
  */
  HAL_RCCEx_EnableMSIPLLMode();
}

void PeriphCommonClock_Config(void)
{
  RCC_PeriphCLKInitTypeDef PeriphClkInit = {0};

  /** Initializes the peripherals clock
  */
  PeriphClkInit.PeriphClockSelection = RCC_PERIPHCLK_SAI1|RCC_PERIPHCLK_USB
                              |RCC_PERIPHCLK_SDMMC1|RCC_PERIPHCLK_ADC;
  PeriphClkInit.Sai1ClockSelection = RCC_SAI1CLKSOURCE_PLLSAI1;
  PeriphClkInit.AdcClockSelection = RCC_ADCCLKSOURCE_PLLSAI1;
  PeriphClkInit.UsbClockSelection = RCC_USBCLKSOURCE_PLLSAI1;
  PeriphClkInit.Sdmmc1ClockSelection = RCC_SDMMC1CLKSOURCE_PLLSAI1;
  PeriphClkInit.PLLSAI1.PLLSAI1Source = RCC_PLLSOURCE_MSI;
  PeriphClkInit.PLLSAI1.PLLSAI1M = 1;
  PeriphClkInit.PLLSAI1.PLLSAI1N = 24;
  PeriphClkInit.PLLSAI1.PLLSAI1P = RCC_PLLP_DIV2;
  PeriphClkInit.PLLSAI1.PLLSAI1Q = RCC_PLLQ_DIV2;
  PeriphClkInit.PLLSAI1.PLLSAI1R = RCC_PLLR_DIV2;
  PeriphClkInit.PLLSAI1.PLLSAI1ClockOut = RCC_PLLSAI1_SAI1CLK|RCC_PLLSAI1_48M2CLK
                              |RCC_PLLSAI1_ADC1CLK;
  if (HAL_RCCEx_PeriphCLKConfig(&PeriphClkInit) != HAL_OK)
  {
    Error_Handler();
  }
}

/* USER CODE BEGIN 4 */

void tofTestRegisterRead(void) {
	HAL_StatusTypeDef status;
	uint8_t pData;
	status = HAL_I2C_Mem_Read(&hi2c1, 0x52, 0xC0, 1, &pData, 1, HAL_TIMEOUT);
	// pData should be 0xEE
	if(status == HAL_OK) {
		printf("good");
	}
}

void drawBubble(struct Bubble *bubble) {

	if(!bubble->redraw) return;

	if(!bubble->selected) {
		BSP_LCD_SetTextColor( bubble->colour_inactive );
		BSP_LCD_FillCircle(bubble->x, bubble->y, bubble->radius);
	} else {
		BSP_LCD_SetTextColor( bubble->colour_active );
		BSP_LCD_FillCircle(bubble->x, bubble->y, bubble->radius);
	}

	bubble->redraw = false;

}

void deselectBubbles(uint8_t skip) {

	for(uint8_t i=0; i<num_bubbles; i++) {
		struct Bubble *b = &ui_bubbles[i];
		if(b->type == 1) { // ui bubbles
			if(i == skip) continue;
			b->selected = false;
			b->redraw = true;
		}
	}

}

void uiSetup(void) {

	uint16_t radius = 30;
	uint16_t hit_diameter = 35;
	uint16_t y = 50;

	// left bubble
	ui_bubbles[0].x = 40;
	ui_bubbles[0].y = y;
	ui_bubbles[0].radius = radius;
	ui_bubbles[0].hit_diameter = hit_diameter;
	ui_bubbles[0].selected = false;
	ui_bubbles[0].colour_active = LCD_COLOR_GREEN;
	ui_bubbles[0].colour_inactive = LCD_COLOR_CYAN;
	ui_bubbles[0].redraw = true;
	ui_bubbles[0].type = 1;
	ui_bubbles[0].last_selected = 0;

	// middle bubble
	ui_bubbles[1].x = 120;
	ui_bubbles[1].y = y;
	ui_bubbles[1].radius = radius;
	ui_bubbles[1].hit_diameter = hit_diameter;
	ui_bubbles[1].selected = true;
	ui_bubbles[1].colour_active = LCD_COLOR_GREEN;
	ui_bubbles[1].colour_inactive = LCD_COLOR_LIGHTBLUE;
	ui_bubbles[1].redraw = true;
	ui_bubbles[1].type = 1;
	ui_bubbles[1].last_selected = 0;

	// right bubble
	ui_bubbles[2].x = 200;
	ui_bubbles[2].y = y;
	ui_bubbles[2].radius = radius;
	ui_bubbles[2].hit_diameter = hit_diameter;
	ui_bubbles[2].selected = false;
	ui_bubbles[2].colour_active = LCD_COLOR_GREEN;
	ui_bubbles[2].colour_inactive = LCD_COLOR_LIGHTMAGENTA;
	ui_bubbles[2].redraw = true;
	ui_bubbles[2].type = 1;
	ui_bubbles[2].last_selected = 0;

	// go bubble
	ui_bubbles[3].x = 120;
	ui_bubbles[3].y = 170;
	ui_bubbles[3].radius = 45;
	ui_bubbles[3].hit_diameter = 50;
	ui_bubbles[3].selected = true;
	ui_bubbles[3].colour_active = LCD_COLOR_GREEN;
	ui_bubbles[3].colour_inactive = LCD_COLOR_BLUE;
	ui_bubbles[3].redraw = true;
	ui_bubbles[3].type = 2;
	ui_bubbles[3].last_selected = 0;

}

void reconfigureFromSleep(void) {
	/* System is Low Power Run mode when exiting Low Power Sleep mode,
		 disable low power run mode and reset the clock to initialization configuration */
	HAL_PWREx_DisableLowPowerRunMode();

	/* Configure the system clock for the RUN mode */
	SystemClock_Config();

	/* Configure the peripherals common clocks */
	PeriphCommonClock_Config();

	/* Re-init GPIOs */
	MX_GPIO_Init();

	/* Resume Tick interrupt if disabled prior to Low Power Sleep mode entry */
	HAL_ResumeTick();
}

void awakeFromSleep(void) {

	// turn on LD1, LD2
	BSP_LED_On(LED2_PIN); // LD1 orange turns on
	HAL_GPIO_WritePin(LED2_GPIO_PORT, LED2_PIN, GPIO_PIN_RESET); // LD2 green turns on
	if(PWR_ANALYSIS) HAL_Delay(PWR_ANALYSIS_DELAY);

	// turn on lcd
	BSP_LCD_DisplayOn();
	DIMMED_SCREEN = false;
	if(PWR_ANALYSIS) HAL_Delay(PWR_ANALYSIS_DELAY);

	// turn on laser and test point
	HAL_GPIO_WritePin(ARD_D4_GPIO_Port, ARD_D4_Pin, GPIO_PIN_SET); // laser
	HAL_GPIO_WritePin(ARD_D7_GPIO_Port, ARD_D7_Pin, GPIO_PIN_SET); // test point: timer frequency
	if(PWR_ANALYSIS) HAL_Delay(PWR_ANALYSIS_DELAY);

	// turn on ts
	BSP_TS_ITConfig();
	if(PWR_ANALYSIS) HAL_Delay(PWR_ANALYSIS_DELAY);

	// turn on BT pwr transistor
	HAL_GPIO_WritePin(ARD_D2_GPIO_Port, ARD_D2_Pin, GPIO_PIN_SET);
	if(PWR_ANALYSIS) HAL_Delay(PWR_ANALYSIS_DELAY);

	// set flags
	BT_ENABLED = true;
	ENTER_SLEEP_MODE = false;
	SLEEP_MODE_ACTIVE = false;

}

void enterSleep(void) {

	// turn off ts
	BSP_TS_ITDeConfig();

	// turn off lcd
	BSP_LCD_Clear(LCD_COLOR_WHITE);
	if(DIMMED_SCREEN == true) {
		BSP_LCD_ScreenDimmingOff();
	}
	BSP_LCD_ScreenDimmingConfig(100, 0, 5, 20);
	BSP_LCD_ScreenDimmingOn();
	BSP_LCD_DisplayOff();
	DIMMED_SCREEN = true;
	HAL_Delay(1000); // wait for fade to finish
	HAL_GPIO_WritePin(LCD_BL_CTRL_GPIO_PORT, LCD_BL_CTRL_PIN, GPIO_PIN_RESET); // force the backlight off

	// turn off BT pwr transistor
	HAL_GPIO_WritePin(ARD_D2_GPIO_Port, ARD_D2_Pin, GPIO_PIN_RESET);
	if(PWR_ANALYSIS) HAL_Delay(PWR_ANALYSIS_DELAY);

	// turn off LD1, LD2
	BSP_LED_Off(LED2_PIN); // LD1 orange turns off
	HAL_GPIO_WritePin(LED2_GPIO_PORT, LED2_PIN, GPIO_PIN_SET); // LD2 green turns off
	if(PWR_ANALYSIS) HAL_Delay(PWR_ANALYSIS_DELAY);

	// turn off laser and test point
	HAL_GPIO_WritePin(ARD_D4_GPIO_Port, ARD_D4_Pin, GPIO_PIN_RESET); // laser
	HAL_GPIO_WritePin(ARD_D7_GPIO_Port, ARD_D7_Pin, GPIO_PIN_RESET); // test point: timer frequency
	if(PWR_ANALYSIS) HAL_Delay(PWR_ANALYSIS_DELAY);

	// set flags
	BT_ENABLED = false;
	ENTER_SLEEP_MODE = false;
	SLEEP_MODE_ACTIVE = true;

}

void HAL_GPIO_EXTI_Callback(uint16_t GPIO_Pin)
{

	// DOWN: enter sleep mode
	// LEFT: wake up (event)
	// RIGHT: toggle bt enabled

	if(GPIO_Pin == JOY_DOWN_Pin) {
		// set flag to enter sleep mode
		ENTER_SLEEP_MODE = true;
	}

	if(GPIO_Pin == JOY_RIGHT_Pin) {

		if(BT_ENABLED) {
			HAL_GPIO_WritePin(ARD_D2_GPIO_Port, ARD_D2_Pin, GPIO_PIN_RESET); // turn off BT pwr transistor
		} else {
			HAL_GPIO_WritePin(ARD_D2_GPIO_Port, ARD_D2_Pin, GPIO_PIN_SET); // turn on BT pwr transistor
		}

		BT_ENABLED = !BT_ENABLED;

	}

}

/**
  * @brief SYSTICK callback
  * @param None
  * @retval None
  */
void HAL_SYSTICK_Callback(void)
{
  //HAL_IncTick(); // it's already incremented in _it.c
  if (TimingDelay != 0) {
    TimingDelay--;
  } else {
    TimingDelay = LED_TOGGLE_DELAY;
  }
}

/* USER CODE END 4 */

void Error_Handler(void)
{
  __disable_irq();
  while (1)
  {
  }
}
